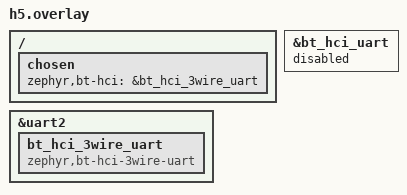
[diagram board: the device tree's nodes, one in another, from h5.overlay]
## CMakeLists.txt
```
# SPDX-License-Identifier: Apache-2.0

cmake_minimum_required(VERSION 3.20.0)
find_package(Zephyr REQUIRED HINTS $ENV{ZEPHYR_BASE})
project(bluetooth_init)

FILE(GLOB app_sources src/*.c)
target_sources(app PRIVATE ${app_sources})
```

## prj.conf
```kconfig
CONFIG_BT=y
CONFIG_LOG=y
CONFIG_ZTEST=y
```

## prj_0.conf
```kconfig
CONFIG_BT=y
CONFIG_ZTEST=y
```

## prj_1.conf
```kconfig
CONFIG_BT=y
CONFIG_BT_PERIPHERAL=y
CONFIG_ZTEST=y
```

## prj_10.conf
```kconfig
CONFIG_BT=y
CONFIG_BT_PERIPHERAL=y
CONFIG_BT_CENTRAL=y
CONFIG_BT_SMP=y
CONFIG_BT_SIGNING=y
CONFIG_BT_SMP_SC_ONLY=y
CONFIG_BT_TINYCRYPT_ECC=y
CONFIG_BT_USE_DEBUG_KEYS=y
CONFIG_ZTEST=y
```

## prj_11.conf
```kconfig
CONFIG_BT=y
CONFIG_BT_PERIPHERAL=y
CONFIG_BT_CENTRAL=y
CONFIG_BT_SMP=y
CONFIG_BT_SIGNING=y
CONFIG_BT_SMP_SC_ONLY=y
CONFIG_BT_TINYCRYPT_ECC=y
CONFIG_BT_USE_DEBUG_KEYS=y
CONFIG_BT_L2CAP_DYNAMIC_CHANNEL=y
CONFIG_BT_GATT_CLIENT=y
CONFIG_ZTEST=y
```

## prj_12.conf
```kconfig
CONFIG_BT=y
CONFIG_BT_PERIPHERAL=y
CONFIG_BT_SMP=y
CONFIG_BT_SIGNING=y
CONFIG_BT_SMP_SC_ONLY=y
CONFIG_BT_TINYCRYPT_ECC=y
CONFIG_BT_USE_DEBUG_KEYS=y
CONFIG_BT_L2CAP_DYNAMIC_CHANNEL=y
CONFIG_BT_GATT_CLIENT=y
CONFIG_ZTEST=y
```

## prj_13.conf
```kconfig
CONFIG_BT=y
CONFIG_BT_CENTRAL=y
CONFIG_BT_SMP=y
CONFIG_BT_SIGNING=y
CONFIG_BT_SMP_SC_ONLY=y
CONFIG_BT_TINYCRYPT_ECC=y
CONFIG_BT_USE_DEBUG_KEYS=y
CONFIG_BT_L2CAP_DYNAMIC_CHANNEL=y
CONFIG_BT_GATT_CLIENT=y
CONFIG_ZTEST=y
```

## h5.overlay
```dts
/ {
	chosen {
		zephyr,bt-hci = &bt_hci_3wire_uart;
	};
};

&bt_hci_uart {
	status = "disabled";
};

&uart2 {
	bt_hci_3wire_uart: bt_hci_3wire_uart {
		compatible = "zephyr,bt-hci-3wire-uart";
		status = "okay";
	};
};
```

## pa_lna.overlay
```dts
/ {
	nrf_radio_fem: fem {
		compatible = "generic-fem-two-ctrl-pins";
		ctx-gpios = <&gpio0 26 0>;
		ctx-settle-time-us = <5>;
		crx-gpios = <&gpio0 27 0>;
		crx-settle-time-us = <5>;
	};
};

&radio {
	fem = <&nrf_radio_fem>;
};
```

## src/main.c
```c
/* main.c - Application main entry point */

/*
 * Copyright (c) 2015-2016 Intel Corporation
 *
 * SPDX-License-Identifier: Apache-2.0
 */

#include <zephyr/types.h>
#include <stddef.h>
#include <zephyr/sys/printk.h>
#include <zephyr/ztest.h>

#include <zephyr/bluetooth/bluetooth.h>

ZTEST_SUITE(test_bluetooth_init, NULL, NULL, NULL, NULL, NULL);

ZTEST(test_bluetooth_init, test_init)
{
	zassert_false(bt_enable(NULL), "Bluetooth init failed");
}
```
